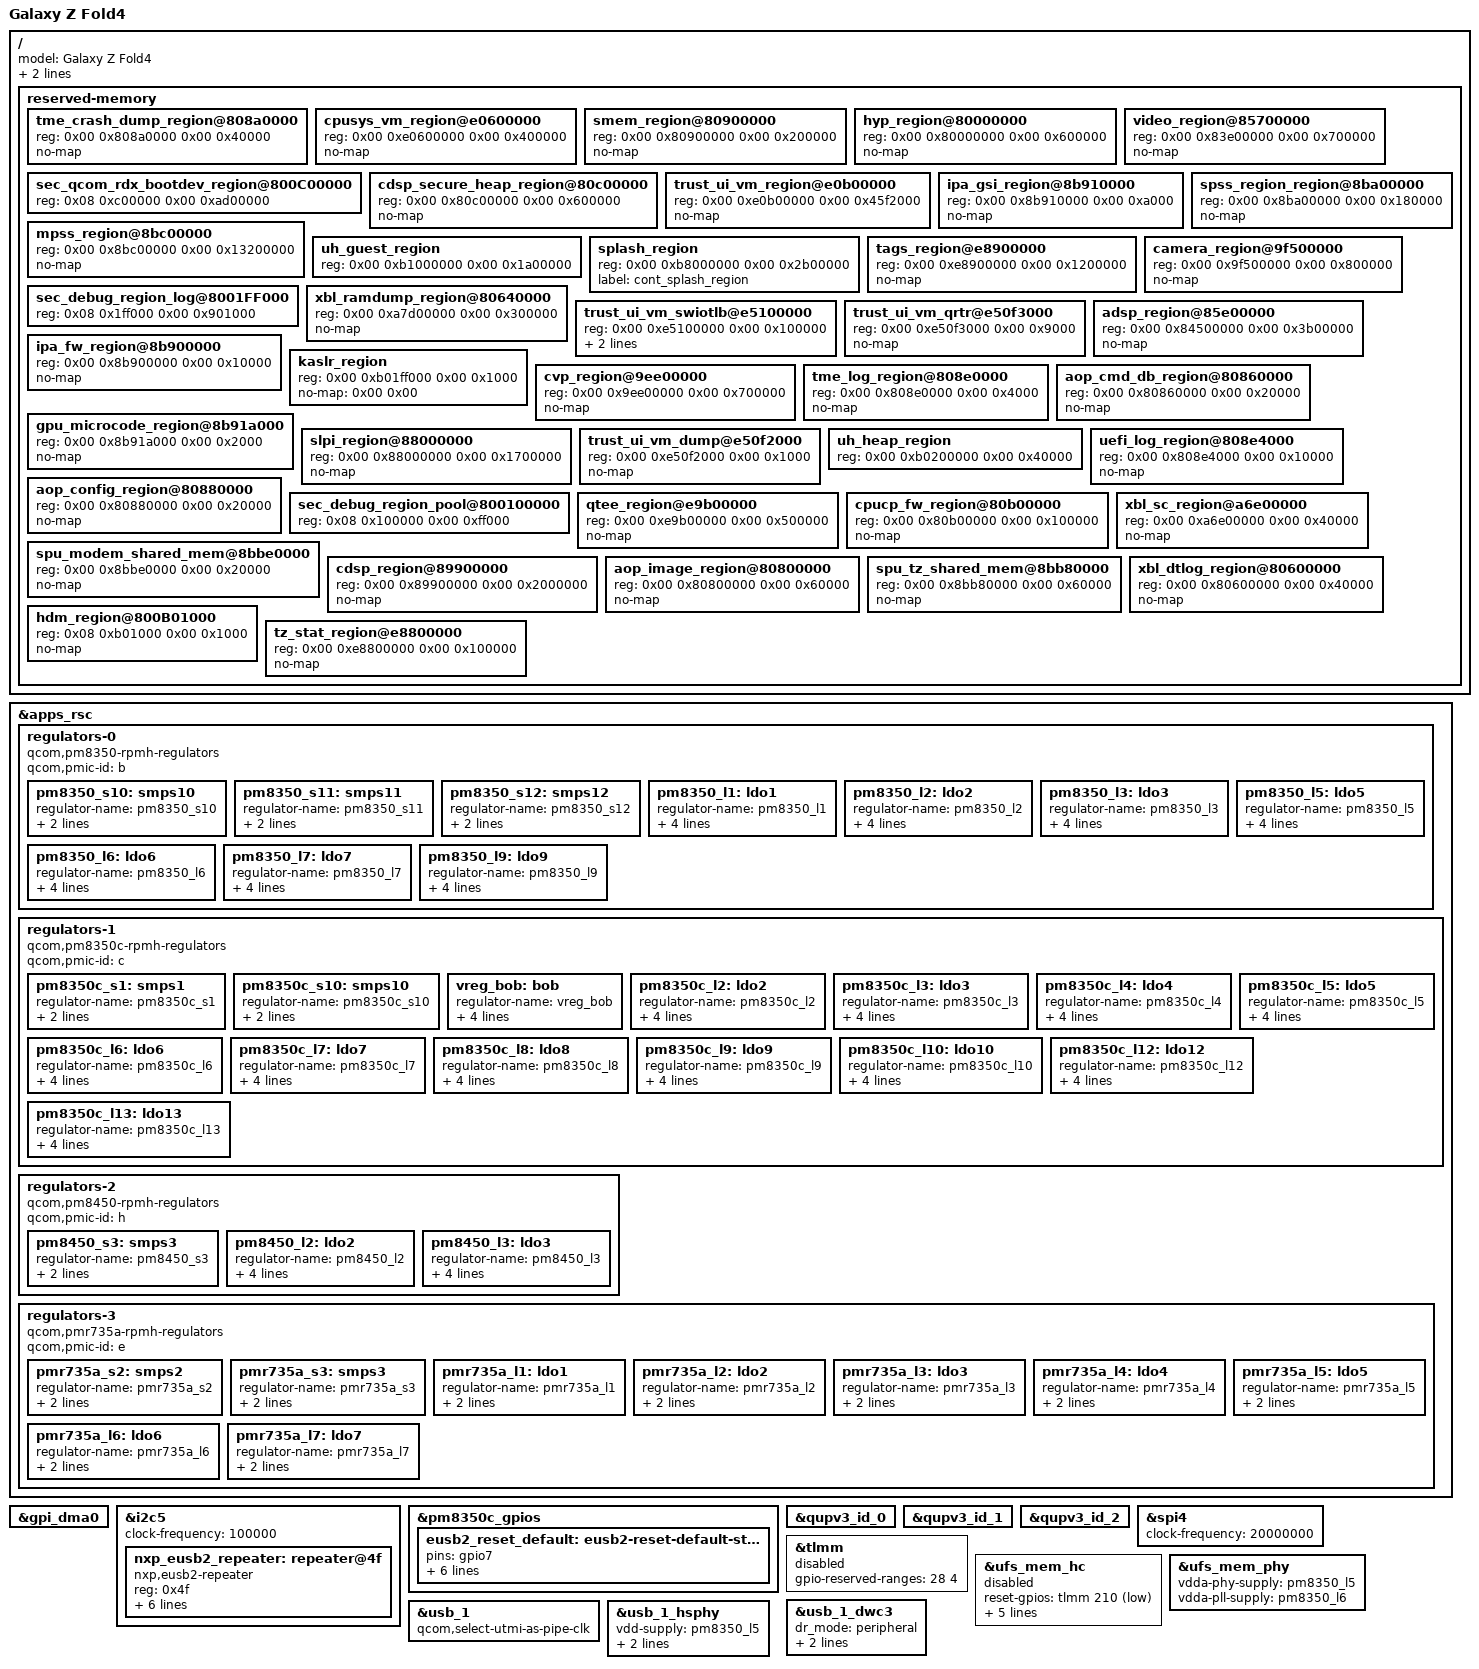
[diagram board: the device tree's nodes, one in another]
// SPDX-License-Identifier: GPL-2.0-only
/*
 * Copyright (c) 2024, The Linux Foundation. All rights reserved.
 */

/dts-v1/;

#include <dt-bindings/arm/qcom,ids.h>
#include <dt-bindings/regulator/qcom,rpmh-regulator.h>
#include <dt-bindings/leds/common.h>
#include <dt-bindings/pinctrl/qcom,pmic-gpio.h>

#include "sm8475.dtsi"
#include "pm8350.dtsi"
#include "pm8350b.dtsi"
#include "pm8350c.dtsi"
#include "pm8450.dtsi"
#include "pmk8350.dtsi"
#include "pmr735a.dtsi"

/ {
	model = "Galaxy Z Fold4";
	chassis-type = "phablet";

	qcom,msm-id = <QCOM_ID_SM8475 0x10000>;

	reserved-memory {
		/* Clear this up, this is awful */
		tme_crash_dump_region@808a0000 {
			reg = <0x00 0x808a0000 0x00 0x40000>;
			no-map;
		};

		cpusys_vm_region@e0600000 {
			reg = <0x00 0xe0600000 0x00 0x400000>;
			no-map;
		};

		smem_region@80900000 {
			reg = <0x00 0x80900000 0x00 0x200000>;
			no-map;
		};

		hyp_region@80000000 {
			reg = <0x00 0x80000000 0x00 0x600000>;
			no-map;
		};

		sec_qcom_rdx_bootdev_region@800C00000 {
			reg = <0x08 0xc00000 0x00 0xad00000>;
		};

		video_region@85700000 {
			reg = <0x00 0x83e00000 0x00 0x700000>;
			no-map;
		};

		cdsp_secure_heap_region@80c00000 {
			reg = <0x00 0x80c00000 0x00 0x600000>;
			no-map;
		};

		trust_ui_vm_region@e0b00000 {
			reg = <0x00 0xe0b00000 0x00 0x45f2000>;
			no-map;
		};

		ipa_gsi_region@8b910000 {
			reg = <0x00 0x8b910000 0x00 0xa000>;
			no-map;
		};

		mpss_region@8bc00000 {
			reg = <0x00 0x8bc00000 0x00 0x13200000>;
			no-map;
		};

		spss_region_region@8ba00000 {
			reg = <0x00 0x8ba00000 0x00 0x180000>;
			no-map;
		};

		uh_guest_region {
			reg = <0x00 0xb1000000 0x00 0x1a00000>;
		};

		splash_region {
			reg = <0x00 0xb8000000 0x00 0x2b00000>;
			label = "cont_splash_region";
		};

		tags_region@e8900000 {
			reg = <0x00 0xe8900000 0x00 0x1200000>;
			no-map;
		};

		camera_region@9f500000 {
			reg = <0x00 0x9f500000 0x00 0x800000>;
			no-map;
		};

		sec_debug_region_log@8001FF000 {
			reg = <0x08 0x1ff000 0x00 0x901000>;
		};

		xbl_ramdump_region@80640000 {
			reg = <0x00 0xa7d00000 0x00 0x300000>;
			no-map;
		};

		trust_ui_vm_swiotlb@e5100000 {
			reg = <0x00 0xe5100000 0x00 0x100000>;
			gunyah-label = <0x12>;
			no-map;
		};

		trust_ui_vm_qrtr@e50f3000 {
			reg = <0x00 0xe50f3000 0x00 0x9000>;
			no-map;
		};

		adsp_region@85e00000 {
			reg = <0x00 0x84500000 0x00 0x3b00000>;
			no-map;
		};

		ipa_fw_region@8b900000 {
			reg = <0x00 0x8b900000 0x00 0x10000>;
			no-map;
		};

		kaslr_region {
			reg = <0x00 0xb01ff000 0x00 0x1000>;
			no-map = <0x00 0x00>;
		};

		cvp_region@9ee00000 {
			reg = <0x00 0x9ee00000 0x00 0x700000>;
			no-map;
		};

		tme_log_region@808e0000 {
			reg = <0x00 0x808e0000 0x00 0x4000>;
			no-map;
		};

		aop_cmd_db_region@80860000 {
			reg = <0x00 0x80860000 0x00 0x20000>;
			no-map;
		};

		gpu_microcode_region@8b91a000 {
			reg = <0x00 0x8b91a000 0x00 0x2000>;
			no-map;
		};

		slpi_region@88000000 {
			reg = <0x00 0x88000000 0x00 0x1700000>;
			no-map;
		};

		trust_ui_vm_dump@e50f2000 {
			reg = <0x00 0xe50f2000 0x00 0x1000>;
			no-map;
		};

		uh_heap_region {
			reg = <0x00 0xb0200000 0x00 0x40000>;
		};

		uefi_log_region@808e4000 {
			reg = <0x00 0x808e4000 0x00 0x10000>;
			no-map;
		};

		aop_config_region@80880000 {
			reg = <0x00 0x80880000 0x00 0x20000>;
			no-map;
		};

		sec_debug_region_pool@800100000 {
			reg = <0x08 0x100000 0x00 0xff000>;
		};

		qtee_region@e9b00000 {
			reg = <0x00 0xe9b00000 0x00 0x500000>;
			no-map;
		};

		cpucp_fw_region@80b00000 {
			reg = <0x00 0x80b00000 0x00 0x100000>;
			no-map;
		};

		xbl_sc_region@a6e00000 {
			reg = <0x00 0xa6e00000 0x00 0x40000>;
			no-map;
		};

		spu_modem_shared_mem@8bbe0000 {
			reg = <0x00 0x8bbe0000 0x00 0x20000>;
			no-map;
		};

		cdsp_region@89900000 {
			reg = <0x00 0x89900000 0x00 0x2000000>;
			no-map;
		};

		aop_image_region@80800000 {
			reg = <0x00 0x80800000 0x00 0x60000>;
			no-map;
		};

		spu_tz_shared_mem@8bb80000 {
			reg = <0x00 0x8bb80000 0x00 0x60000>;
			no-map;
		};

		xbl_dtlog_region@80600000 {
			reg = <0x00 0x80600000 0x00 0x40000>;
			no-map;
		};

		hdm_region@800B01000 {
			reg = <0x08 0xb01000 0x00 0x1000>;
			no-map;
		};

		tz_stat_region@e8800000 {
			reg = <0x00 0xe8800000 0x00 0x100000>;
			no-map;
		};
	};
};


&apps_rsc {
	regulators-0 {
		compatible = "qcom,pm8350-rpmh-regulators";
		qcom,pmic-id = "b";

		/*
		vdd-s1-supply = <&vph_pwr>;
		vdd-s2-supply = <&vph_pwr>;
		vdd-s3-supply = <&vph_pwr>;
		vdd-s4-supply = <&vph_pwr>;
		vdd-s5-supply = <&vph_pwr>;
		vdd-s6-supply = <&vph_pwr>;
		vdd-s7-supply = <&vph_pwr>;
		vdd-s8-supply = <&vph_pwr>;
		vdd-s9-supply = <&vph_pwr>;
		vdd-s10-supply = <&vph_pwr>;
		vdd-s11-supply = <&vph_pwr>;
		vdd-s12-supply = <&vph_pwr>;

		vdd-l1-l4-supply = <&pm8350_s11>;
		vdd-l2-l7-supply = <&vreg_bob>;
		vdd-l3-l5-supply = <&pm8350_s11>;
		vdd-l6-l9-l10-supply = <&pm8350_s12>;
		*/

		/*
		 * ARC regulators:
		 * s5 - gfx.lvl
		 * l8 - lcx.lvl
		 */

		pm8350_s10: smps10 {
			regulator-name = "pm8350_s10";
			regulator-min-microvolt = <1800000>;
			regulator-max-microvolt = <1800000>;
		};

		pm8350_s11: smps11 {
			regulator-name = "pm8350_s11";
			regulator-min-microvolt = <382000>;
			regulator-max-microvolt = <1170000>;
		};

		pm8350_s12: smps12 {
			regulator-name = "pm8350_s12";
			regulator-min-microvolt = <1224000>;
			regulator-max-microvolt = <2040000>;
		};

		pm8350_l1: ldo1 {
			regulator-name = "pm8350_l1";
			regulator-min-microvolt = <830000>;
			regulator-max-microvolt = <920000>;
			regulator-initial-mode = <RPMH_REGULATOR_MODE_HPM>;
		};

		pm8350_l2: ldo2 {
			regulator-name = "pm8350_l2";
			regulator-min-microvolt = <2700000>;
			regulator-max-microvolt = <3300000>;
			regulator-initial-mode = <RPMH_REGULATOR_MODE_HPM>;
		};

		pm8350_l3: ldo3 {
			regulator-name = "pm8350_l3";
			regulator-min-microvolt = <870000>;
			regulator-max-microvolt = <970000>;
			regulator-initial-mode = <RPMH_REGULATOR_MODE_HPM>;
		};

		pm8350_l5: ldo5 {
			regulator-name = "pm8350_l5";
			regulator-min-microvolt = <720000>;
			regulator-max-microvolt = <958000>;
			regulator-initial-mode = <RPMH_REGULATOR_MODE_HPM>;
		};

		pm8350_l6: ldo6 {
			regulator-name = "pm8350_l6";
			regulator-min-microvolt = <1200000>;
			regulator-max-microvolt = <1216000>;
			regulator-initial-mode = <RPMH_REGULATOR_MODE_HPM>;
		};

		pm8350_l7: ldo7 {
			regulator-name = "pm8350_l7";
			regulator-min-microvolt = <2400000>;
			regulator-max-microvolt = <3544000>;
			regulator-initial-mode = <RPMH_REGULATOR_MODE_HPM>;
		};

		pm8350_l9: ldo9 {
			regulator-name = "pm8350_l9";
			regulator-min-microvolt = <1200000>;
			regulator-max-microvolt = <1304000>;
			regulator-initial-mode = <RPMH_REGULATOR_MODE_HPM>;
		};
	};

	regulators-1 {
		compatible = "qcom,pm8350c-rpmh-regulators";
		qcom,pmic-id = "c";

		/*
		vdd-s1-supply = <&vph_pwr>;
		vdd-s2-supply = <&vph_pwr>;
		vdd-s3-supply = <&vph_pwr>;
		vdd-s4-supply = <&vph_pwr>;
		vdd-s5-supply = <&vph_pwr>;
		vdd-s6-supply = <&vph_pwr>;
		vdd-s7-supply = <&vph_pwr>;
		vdd-s8-supply = <&vph_pwr>;
		vdd-s9-supply = <&vph_pwr>;
		vdd-s10-supply = <&vph_pwr>;

		vdd-l1-l12-supply = <&pm8350c_s1>;
		vdd-l2-l8-supply = <&pm8350c_s1>;
		vdd-l3-l4-l5-l7-l13-supply = <&vreg_bob>;
		vdd-l6-l9-l11-supply = <&vreg_bob>;
		vdd-l10-supply = <&pm8350_s12>;

		vdd-bob-supply = <&vph_pwr>;
		*/

		/*
		 * ARC regulators:
		 * s2 - mxc.lvl
		 * s4 - mss.lvl
		 * s6 - cx.lvl
		 */

		pm8350c_s1: smps1 {
			regulator-name = "pm8350c_s1";
			regulator-min-microvolt = <1900000>;
			regulator-max-microvolt = <2024000>;
		};

		pm8350c_s10: smps10 {
			regulator-name = "pm8350c_s10";
			regulator-min-microvolt = <1052000>;
			regulator-max-microvolt = <1170000>;
		};

		vreg_bob: bob {
			regulator-name = "vreg_bob";
			regulator-min-microvolt = <3008000>;
			regulator-max-microvolt = <3960000>;
			regulator-initial-mode = <RPMH_REGULATOR_MODE_AUTO>;
		};

		pm8350c_l2: ldo2 {
			regulator-name = "pm8350c_l2";
			regulator-min-microvolt = <1800000>;
			regulator-max-microvolt = <1980000>;
			regulator-initial-mode = <RPMH_REGULATOR_MODE_HPM>;
		};

		pm8350c_l3: ldo3 {
			regulator-name = "pm8350c_l3";
			regulator-min-microvolt = <2700000>;
			regulator-max-microvolt = <3544000>;
			regulator-initial-mode = <RPMH_REGULATOR_MODE_HPM>;
		};

		pm8350c_l4: ldo4 {
			regulator-name = "pm8350c_l4";
			regulator-min-microvolt = <1620000>;
			regulator-max-microvolt = <3300000>;
			regulator-initial-mode = <RPMH_REGULATOR_MODE_HPM>;
		};

		pm8350c_l5: ldo5 {
			regulator-name = "pm8350c_l5";
			regulator-min-microvolt = <1620000>;
			regulator-max-microvolt = <3300000>;
			regulator-initial-mode = <RPMH_REGULATOR_MODE_HPM>;
		};

		pm8350c_l6: ldo6 {
			regulator-name = "pm8350c_l6";
			regulator-min-microvolt = <1800000>;
			regulator-max-microvolt = <3544000>;
			regulator-initial-mode = <RPMH_REGULATOR_MODE_HPM>;
		};

		pm8350c_l7: ldo7 {
			regulator-name = "pm8350c_l7";
			regulator-min-microvolt = <3000000>;
			regulator-max-microvolt = <3544000>;
			regulator-initial-mode = <RPMH_REGULATOR_MODE_HPM>;
		};

		pm8350c_l8: ldo8 {
			regulator-name = "pm8350c_l8";
			regulator-min-microvolt = <1800000>;
			regulator-max-microvolt = <2000000>;
			regulator-initial-mode = <RPMH_REGULATOR_MODE_HPM>;
		};

		pm8350c_l9: ldo9 {
			regulator-name = "pm8350c_l9";
			regulator-min-microvolt = <2700000>;
			regulator-max-microvolt = <3544000>;
			regulator-initial-mode = <RPMH_REGULATOR_MODE_HPM>;
		};

		pm8350c_l10: ldo10 {
			regulator-name = "pm8350c_l10";
			regulator-min-microvolt = <1200000>;
			regulator-max-microvolt = <1304000>;
			regulator-initial-mode = <RPMH_REGULATOR_MODE_HPM>;
		};

		pm8350c_l12: ldo12 {
			regulator-name = "pm8350c_l12";
			regulator-min-microvolt = <1800000>;
			regulator-max-microvolt = <1980000>;
			regulator-initial-mode = <RPMH_REGULATOR_MODE_HPM>;
		};

		pm8350c_l13: ldo13 {
			regulator-name = "pm8350c_l13";
			regulator-min-microvolt = <2700000>;
			regulator-max-microvolt = <3544000>;
			regulator-initial-mode = <RPMH_REGULATOR_MODE_HPM>;
		};
	};

	regulators-2 {
		compatible = "qcom,pm8450-rpmh-regulators";
		qcom,pmic-id = "h";

		/*
		vdd-s1-supply = <&vph_pwr>;
		vdd-s2-supply = <&vph_pwr>;
		vdd-s3-supply = <&vph_pwr>;
		vdd-s4-supply = <&vph_pwr>;
		vdd-s5-supply = <&vph_pwr>;
		vdd-s6-supply = <&vph_pwr>;

		vdd-l2-supply = <&vreg_bob>;
		vdd-l3-supply = <&vreg_bob>;
		vdd-l4-supply = <&vreg_bob>;
		*/

		/*
		 * ARC regulators:
		 * S2 - ebi.lvl
		 * S4 - mmcx.lvl
		 * S6 - mx.lvl
		 * L1 - lmx.lvl
		 */

		pm8450_s3: smps3 {
			regulator-name = "pm8450_s3";
			regulator-min-microvolt = <470000>;
			regulator-max-microvolt = <570000>;
		};

		pm8450_l2: ldo2 {
			regulator-name = "pm8450_l2";
			regulator-min-microvolt = <820000>;
			regulator-max-microvolt = <958000>;
			regulator-initial-mode = <RPMH_REGULATOR_MODE_HPM>;
		};

		pm8450_l3: ldo3 {
			regulator-name = "pm8450_l3";
			regulator-min-microvolt = <866000>;
			regulator-max-microvolt = <958000>;
			regulator-initial-mode = <RPMH_REGULATOR_MODE_HPM>;
		};
	};

	regulators-3 {
		compatible = "qcom,pmr735a-rpmh-regulators";
		qcom,pmic-id = "e";

		/*
		vdd-s1-supply = <&vph_pwr>;
		vdd-s2-supply = <&vph_pwr>;
		vdd-s3-supply = <&vph_pwr>;

		vdd-l1-l2-supply = <&pmr735a_s2>;
		vdd-l3-supply = <&pmr735a_s1>;
		vdd-l4-supply = <&pm8350c_s1>;
		vdd-l5-l6-supply = <&pm8350c_s1>;
		vdd-l7-bob-supply = <&vreg_bob>;
		*/

		pmr735a_s2: smps2 {
			regulator-name = "pmr735a_s2";
			regulator-min-microvolt = <500000>;
			regulator-max-microvolt = <1040000>;
		};

		pmr735a_s3: smps3 {
			regulator-name = "pmr735a_s3";
			regulator-min-microvolt = <300000>;
			regulator-max-microvolt = <2352000>;
		};

		pmr735a_l1: ldo1 {
			regulator-name = "pmr735a_l1";
			regulator-min-microvolt = <800000>;
			regulator-max-microvolt = <880000>;
		};

		pmr735a_l2: ldo2 {
			regulator-name = "pmr735a_l2";
			regulator-min-microvolt = <480000>;
			regulator-max-microvolt = <1200000>;
		};

		pmr735a_l3: ldo3 {
			regulator-name = "pmr735a_l3";
			regulator-min-microvolt = <1200000>;
			regulator-max-microvolt = <1200000>;
		};

		pmr735a_l4: ldo4 {
			regulator-name = "pmr735a_l4";
			regulator-min-microvolt = <1776000>;
			regulator-max-microvolt = <1776000>;
		};

		pmr735a_l5: ldo5 {
			regulator-name = "pmr735a_l5";
			regulator-min-microvolt = <880000>;
			regulator-max-microvolt = <920000>;
		};

		pmr735a_l6: ldo6 {
			regulator-name = "pmr735a_l6";
			regulator-min-microvolt = <1200000>;
			regulator-max-microvolt = <1200000>;
		};

		pmr735a_l7: ldo7 {
			regulator-name = "pmr735a_l7";
			regulator-min-microvolt = <2800000>;
			regulator-max-microvolt = <2800000>;
		};
	};
};

&gpi_dma0 {
	status = "okay";
};

&i2c5 {
	clock-frequency = <100000>;
	status = "okay";

	nxp_eusb2_repeater: repeater@4f {
		compatible = "nxp,eusb2-repeater";
		reg = <0x4f>;
		vdd18-supply = <&pm8350_s10>;
		vdd3-supply = <&pm8350_l2>;
		reset-gpio = <&pm8350c_gpios 7 GPIO_ACTIVE_HIGH>;
		pinctrl-names = "default";
		pinctrl-0 = <&eusb2_reset_default>;
		#phy-cells = <0>;
		qcom,param-override-seq =
				/* Rx squelch detection threshold to 110mV; default is 125mV */
				<0x40 0x06
				/*
				 * Tx Deemphasis to 2dB, Tx Deemphasis bit duration to 0.8UI;
				 * default is 0 for both
				 */
				0x22 0x07
				/* Output Voltage Swing to 550mV; default is 450mV */
				0x64 0x08>;
	};
};

&pm8350c_gpios {
	eusb2_reset_default: eusb2-reset-default-state {
		pins = "gpio7";
		function = PMIC_GPIO_FUNC_NORMAL;
		input-enable;
		output-enable;
		bias-disable;
		power-source = <1>;	/* 1.8V */
		qcom,drive-strength = <PMIC_GPIO_STRENGTH_MED>;
	};
};

&qupv3_id_0 {
	status = "okay";
};

&qupv3_id_1 {
	status = "okay";
};

&qupv3_id_2 {
	status = "okay";
};

&spi4 {
	clock-frequency = <20000000>;
	status = "okay";

	/* goodix-berlin@0 goodix,brl-d */
};

&tlmm {
	status = "disabled";
	gpio-reserved-ranges = <28 4>;
};

&ufs_mem_hc {
	status = "disabled";

	reset-gpios = <&tlmm 210 GPIO_ACTIVE_LOW>;

	vcc-supply = <&pm8350_l7>;
	vcc-max-microamp = <1100000>;
	vccq-supply = <&pm8350_l9>;
	vccq-max-microamp = <1200000>;
	vdd-hba-supply = <&pm8350_l9>;
};

&ufs_mem_phy {
	status = "okay";

	vdda-phy-supply = <&pm8350_l5>;
	vdda-pll-supply = <&pm8350_l6>;
};

&usb_1 {
	/* USB 2.0 only */
	qcom,select-utmi-as-pipe-clk;
	status = "okay";
};

&usb_1_dwc3 {
	dr_mode = "peripheral";
	maximum-speed = "high-speed";
	/* Remove USB3 phy */
	phys = <&usb_1_hsphy>;
	phy-names = "usb2-phy";
};

&usb_1_hsphy {
	vdd-supply = <&pm8350_l5>;
	vdda12-supply = <&pm8350c_l10>;

	phys = <&nxp_eusb2_repeater>;

	status = "okay";
};
